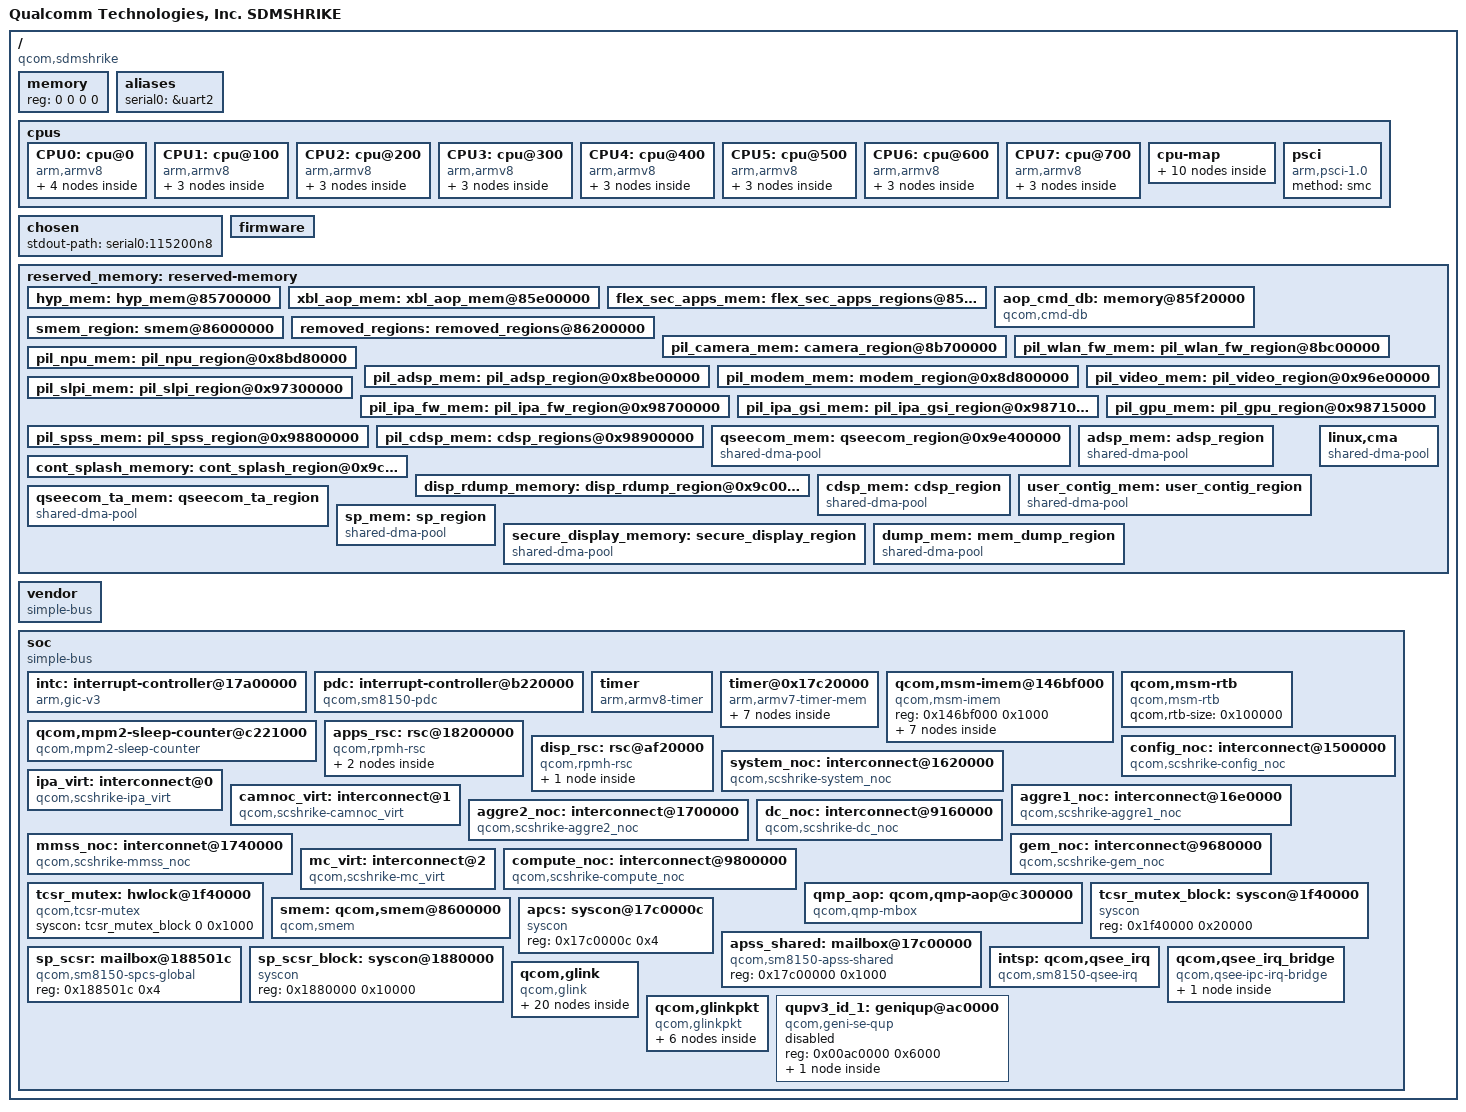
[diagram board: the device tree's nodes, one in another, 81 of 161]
#include <dt-bindings/clock/qcom,rpmh.h>
#include <dt-bindings/interconnect/qcom,icc.h>
#include <dt-bindings/interconnect/qcom,scshrike.h>
#include <dt-bindings/interrupt-controller/arm-gic.h>
#include <dt-bindings/soc/qcom,rpmh-rsc.h>

/ {
	model = "Qualcomm Technologies, Inc. SDMSHRIKE";
	compatible = "qcom,sdmshrike";
	qcom,msm-name = "SDMSHRIKE";
	qcom,msm-id = <340 0x10000>;
	interrupt-parent = <&intc>;

	#address-cells = <2>;
	#size-cells = <2>;
	memory { device_type = "memory"; reg = <0 0 0 0>; };

	aliases {
		serial0 = &uart2;
	};

	cpus {
		#address-cells = <2>;
		#size-cells = <0>;

		CPU0: cpu@0 {
			device_type = "cpu";
			compatible = "arm,armv8";
			reg = <0x0 0x0>;
			enable-method = "psci";
			capacity-dmips-mhz = <1024>;
			cache-size = <0x8000>;
			next-level-cache = <&L2_0>;
			#cooling-cells = <2>;
			L2_0: l2-cache {
			      compatible = "arm,arch-cache";
			      cache-size = <0x20000>;
			      cache-level = <2>;
			      next-level-cache = <&L3_0>;

				L3_0: l3-cache {
				      compatible = "arm,arch-cache";
				      cache-size = <0x400000>;
				      cache-level = <3>;
				};
			};

			L1_I_0: l1-icache {
				compatible = "arm,arch-cache";
				qcom,dump-size = <0xa000>;
			};

			L1_D_0: l1-dcache {
				compatible = "arm,arch-cache";
				qcom,dump-size = <0xa000>;
			};
		};

		CPU1: cpu@100 {
			device_type = "cpu";
			compatible = "arm,armv8";
			reg = <0x0 0x100>;
			enable-method = "psci";
			capacity-dmips-mhz = <1024>;
			cache-size = <0x8000>;
			next-level-cache = <&L2_1>;
			#cooling-cells = <2>;
			L2_1: l2-cache {
			      compatible = "arm,arch-cache";
			      cache-size = <0x20000>;
			      cache-level = <2>;
			      next-level-cache = <&L3_0>;
			};

			L1_I_100: l1-icache {
				compatible = "arm,arch-cache";
				qcom,dump-size = <0xa000>;
			};

			L1_D_100: l1-dcache {
				compatible = "arm,arch-cache";
				qcom,dump-size = <0xa000>;
			};
		};

		CPU2: cpu@200 {
			device_type = "cpu";
			compatible = "arm,armv8";
			reg = <0x0 0x200>;
			enable-method = "psci";
			capacity-dmips-mhz = <1024>;
			cache-size = <0x8000>;
			next-level-cache = <&L2_2>;
			#cooling-cells = <2>;
			L2_2: l2-cache {
			      compatible = "arm,arch-cache";
			      cache-size = <0x20000>;
			      cache-level = <2>;
			      next-level-cache = <&L3_0>;
			};

			L1_I_200: l1-icache {
				compatible = "arm,arch-cache";
				qcom,dump-size = <0xa000>;
			};

			L1_D_200: l1-dcache {
				compatible = "arm,arch-cache";
				qcom,dump-size = <0xa000>;
			};
		};

		CPU3: cpu@300 {
			device_type = "cpu";
			compatible = "arm,armv8";
			reg = <0x0 0x300>;
			enable-method = "psci";
			capacity-dmips-mhz = <1024>;
			cache-size = <0x8000>;
			next-level-cache = <&L2_3>;
			#cooling-cells = <2>;
			L2_3: l2-cache {
			      compatible = "arm,arch-cache";
			      cache-size = <0x20000>;
			      cache-level = <2>;
			      next-level-cache = <&L3_0>;
			};

			L1_I_300: l1-icache {
				compatible = "arm,arch-cache";
				qcom,dump-size = <0xa000>;
			};

			L1_D_300: l1-dcache {
				compatible = "arm,arch-cache";
				qcom,dump-size = <0xa000>;
			};
		};

		CPU4: cpu@400 {
			device_type = "cpu";
			compatible = "arm,armv8";
			reg = <0x0 0x400>;
			enable-method = "psci";
			capacity-dmips-mhz = <1740>;
			cache-size = <0x20000>;
			next-level-cache = <&L2_4>;
			#cooling-cells = <2>;
			L2_4: l2-cache {
			      compatible = "arm,arch-cache";
			      cache-size = <0x80000>;
			      cache-level = <2>;
			      next-level-cache = <&L3_0>;
			};

			L1_I_400: l1-icache {
				compatible = "arm,arch-cache";
				qcom,dump-size = <0x14000>;
			};

			L1_D_400: l1-dcache {
				compatible = "arm,arch-cache";
				qcom,dump-size = <0x14000>;
			};
		};

		CPU5: cpu@500 {
			device_type = "cpu";
			compatible = "arm,armv8";
			reg = <0x0 0x500>;
			enable-method = "psci";
			capacity-dmips-mhz = <1740>;
			cache-size = <0x20000>;
			next-level-cache = <&L2_5>;
			#cooling-cells = <2>;
			L2_5: l2-cache {
			      compatible = "arm,arch-cache";
			      cache-size = <0x80000>;
			      cache-level = <2>;
			      next-level-cache = <&L3_0>;
			};

			L1_I_500: l1-icache {
				compatible = "arm,arch-cache";
				qcom,dump-size = <0x14000>;
			};

			L1_D_500: l1-dcache {
				compatible = "arm,arch-cache";
				qcom,dump-size = <0x14000>;
			};
		};

		CPU6: cpu@600 {
			device_type = "cpu";
			compatible = "arm,armv8";
			reg = <0x0 0x600>;
			enable-method = "psci";
			capacity-dmips-mhz = <1740>;
			cache-size = <0x20000>;
			next-level-cache = <&L2_6>;
			#cooling-cells = <2>;
			L2_6: l2-cache {
			      compatible = "arm,arch-cache";
			      cache-size = <0x80000>;
			      cache-level = <2>;
			      next-level-cache = <&L3_0>;
			};

			L1_I_600: l1-icache {
				compatible = "arm,arch-cache";
				qcom,dump-size = <0x14000>;
			};

			L1_D_600: l1-dcache {
				compatible = "arm,arch-cache";
				qcom,dump-size = <0x14000>;
			};
		};

		CPU7: cpu@700 {
			device_type = "cpu";
			compatible = "arm,armv8";
			reg = <0x0 0x700>;
			enable-method = "psci";
			capacity-dmips-mhz = <1740>;
			cache-size = <0x20000>;
			next-level-cache = <&L2_7>;
			#cooling-cells = <2>;
			L2_7: l2-cache {
			      compatible = "arm,arch-cache";
			      cache-size = <0x80000>;
			      cache-level = <2>;
			      next-level-cache = <&L3_0>;
			};

			L1_I_700: l1-icache {
				compatible = "arm,arch-cache";
				qcom,dump-size = <0x14000>;
			};

			L1_D_700: l1-dcache {
				compatible = "arm,arch-cache";
				qcom,dump-size = <0x14000>;
			};
		};

		cpu-map {
			cluster0 {
				core0 {
					cpu = <&CPU0>;
				};

				core1 {
					cpu = <&CPU1>;
				};

				core2 {
					cpu = <&CPU2>;
				};

				core3 {
					cpu = <&CPU3>;
				};
			};

			cluster1 {
				core0 {
					cpu = <&CPU4>;
				};

				core1 {
					cpu = <&CPU5>;
				};

				core2 {
					cpu = <&CPU6>;
				};

				core3 {
					cpu = <&CPU7>;
				};
			};
		};

		psci {
			compatible = "arm,psci-1.0";
			method = "smc";
		};
	};

	chosen {
		stdout-path = "serial0:115200n8";
	};

	firmware: firmware {
	};

	reserved_memory: reserved-memory {
		#address-cells = <2>;
		#size-cells = <2>;
		ranges;

		hyp_mem: hyp_mem@85700000 {
			no-map;
			reg = <0x0 0x85700000 0x0 0x600000>;
		};

		xbl_aop_mem: xbl_aop_mem@85e00000 {
			no-map;
			reg = <0x0 0x85e00000 0x0 0x140000>;
		};

		flex_sec_apps_mem: flex_sec_apps_regions@85ffd000 {
			no-map;
			reg = <0x0 0x85ffd000 0x0 0x3000>;
		};

		aop_cmd_db: memory@85f20000 {
			compatible = "qcom,cmd-db";
			reg = <0x0 0x85f20000 0x0 0x20000>;
			no-map;
		};

		smem_region: smem@86000000 {
			no-map;
			reg = <0x0 0x86000000 0x0 0x200000>;
		};

		removed_regions: removed_regions@86200000 {
			no-map;
			reg = <0x0 0x86200000 0x0 0x5500000>;
		};

		pil_camera_mem: camera_region@8b700000 {
			no-map;
			reg = <0x0 0x8b700000 0x0 0x500000>;
		};

		pil_wlan_fw_mem: pil_wlan_fw_region@8bc00000 {
			no-map;
			reg = <0x0 0x8bc00000 0x0 0x180000>;
		};

		pil_npu_mem: pil_npu_region@0x8bd80000 {
			no-map;
			reg = <0x0 0x8bd80000 0x0 0x80000>;
		};

		pil_adsp_mem: pil_adsp_region@0x8be00000 {
			no-map;
			reg = <0x0 0x8be00000 0x0 0x1a00000>;
		};

		pil_modem_mem: modem_region@0x8d800000 {
			no-map;
			reg = <0x0 0x8d800000 0x0 0x9600000>;
		};

		pil_video_mem: pil_video_region@0x96e00000 {
			no-map;
			reg = <0x0 0x96e00000 0x0 0x500000>;
		};

		pil_slpi_mem: pil_slpi_region@0x97300000 {
			no-map;
			reg = <0x0 0x97300000 0x0 0x1400000>;
		};

		pil_ipa_fw_mem: pil_ipa_fw_region@0x98700000 {
			no-map;
			reg = <0x0 0x98700000 0x0 0x10000>;
		};

		pil_ipa_gsi_mem: pil_ipa_gsi_region@0x98710000 {
			no-map;
			reg = <0x0 0x98710000 0x0 0x5000>;
		};

		pil_gpu_mem: pil_gpu_region@0x98715000 {
			no-map;
			reg = <0x0 0x98715000 0x0 0x2000>;
		};

		pil_spss_mem: pil_spss_region@0x98800000 {
			no-map;
			reg = <0x0 0x98800000 0x0 0x100000>;
		};

		pil_cdsp_mem: cdsp_regions@0x98900000 {
			no-map;
			reg = <0x0 0x98900000 0x0 0x1400000>;
		};

		qseecom_mem: qseecom_region@0x9e400000 {
			compatible = "shared-dma-pool";
			no-map;
			reg = <0x0 0x9e400000 0x0 0x1400000>;
		};


		cont_splash_memory: cont_splash_region@0x9c000000 {
			reg = <0x0 0x9c000000 0x0 0x02400000>;
			label = "cont_splash_region";
		};

		disp_rdump_memory: disp_rdump_region@0x9c000000 {
			reg = <0x0 0x9c000000 0x0 0x02400000>;
			label = "disp_rdump_region";
		};

		adsp_mem: adsp_region {
			compatible = "shared-dma-pool";
			alloc-ranges = <0x0 0x00000000 0x0 0xffffffff>;
			reusable;
			alignment = <0x0 0x400000>;
			size = <0x0 0x1000000>;
		};

		cdsp_mem: cdsp_region {
			compatible = "shared-dma-pool";
			alloc-ranges = <0x0 0x00000000 0x0 0xffffffff>;
			reusable;
			alignment = <0x0 0x400000>;
			size = <0x0 0x400000>;
		};

		user_contig_mem: user_contig_region {
			compatible = "shared-dma-pool";
			alloc-ranges = <0x0 0x00000000 0x0 0xffffffff>;
			reusable;
			alignment = <0x0 0x400000>;
			size = <0x0 0x1000000>;
		};

		qseecom_ta_mem: qseecom_ta_region {
			compatible = "shared-dma-pool";
			alloc-ranges = <0x0 0x00000000 0x0 0xffffffff>;
			reusable;
			alignment = <0x0 0x400000>;
			size = <0x0 0x1000000>;
		};

		sp_mem: sp_region {  /* SPSS-HLOS ION shared mem */
			compatible = "shared-dma-pool";
			alloc-ranges = <0x0 0x00000000 0x0 0xffffffff>;
			reusable;
			alignment = <0x0 0x400000>;
			size = <0x0 0x800000>;
		};

		secure_display_memory: secure_display_region { /* Secure UI */
			compatible = "shared-dma-pool";
			alloc-ranges = <0x0 0x00000000 0x0 0xffffffff>;
			reusable;
			alignment = <0x0 0x400000>;
			size = <0x0 0xA000000>;
		};

		dump_mem: mem_dump_region {
			compatible = "shared-dma-pool";
			reusable;
			size = <0 0x2400000>;
		};

		/* global autoconfigured region for contiguous allocations */
		linux,cma {
			compatible = "shared-dma-pool";
			alloc-ranges = <0x0 0x00000000 0x0 0xffffffff>;
			reusable;
			alignment = <0x0 0x400000>;
			size = <0x0 0x2800000>;
			linux,cma-default;
		};
	};

	vendor: vendor {
		#address-cells = <1>;
		#size-cells = <1>;
		ranges = <0 0 0 0xffffffff>;
		compatible = "simple-bus";
	};

	soc: soc { };
};

&soc {
	#address-cells = <1>;
	#size-cells = <1>;
	ranges = <0 0 0 0xffffffff>;
	compatible = "simple-bus";

	intc: interrupt-controller@17a00000 {
		compatible = "arm,gic-v3";
		#interrupt-cells = <3>;
		interrupt-controller;
		#redistributor-regions = <1>;
		redistributor-stride = <0x0 0x20000>;
		reg = <0x17a00000 0x10000>,     /* GICD */
		      <0x17a60000 0x100000>;    /* GICR * 8 */
		interrupts = <1 9 4>;
		interrupt-parent = <&intc>;
	};

	pdc: interrupt-controller@b220000 {
		compatible = "qcom,sm8150-pdc";
		reg = <0xb220000 0x30000>, <0x17c000f0 0x64>;
		qcom,pdc-ranges = <0 480 94>, <94 609 31>, <125 63 1>;
		#interrupt-cells = <2>;
		interrupt-parent = <&intc>;
		interrupt-controller;
	};

	timer {
		compatible = "arm,armv8-timer";
		interrupts = <1 1 0xf08>,
			     <1 2 0xf08>,
			     <1 3 0xf08>,
			     <1 0 0xf08>;
		clock-frequency = <19200000>;
	};

	timer@0x17c20000 {
		#address-cells = <1>;
		#size-cells = <1>;
		ranges;
		compatible = "arm,armv7-timer-mem";
		reg = <0x17c20000 0x1000>;
		clock-frequency = <19200000>;

		frame@0x17c21000 {
			frame-number = <0>;
			interrupts = <0 7 0x4>,
				     <0 6 0x4>;
			reg = <0x17c21000 0x1000>,
			      <0x17c22000 0x1000>;
		};

		frame@17c23000 {
			frame-number = <1>;
			interrupts = <0 8 0x4>;
			reg = <0x17c23000 0x1000>;
			status = "disabled";
		};

		frame@17c25000 {
			frame-number = <2>;
			interrupts = <0 9 0x4>;
			reg = <0x17c25000 0x1000>;
			status = "disabled";
		};

		frame@17c27000 {
			frame-number = <3>;
			interrupts = <0 10 0x4>;
			reg = <0x17c26000 0x1000>;
			status = "disabled";
		};

		frame@17c29000 {
			frame-number = <4>;
			interrupts = <0 11 0x4>;
			reg = <0x17c29000 0x1000>;
			status = "disabled";
		};

		frame@17c2b000 {
			frame-number = <5>;
			interrupts = <0 12 0x4>;
			reg = <0x17c2b000 0x1000>;
			status = "disabled";
		};

		frame@17c2d000 {
			frame-number = <6>;
			interrupts = <0 13 0x4>;
			reg = <0x17c2d000 0x1000>;
			status = "disabled";
		};
	};

	qcom,msm-imem@146bf000 {
		compatible = "qcom,msm-imem";
		reg = <0x146bf000 0x1000>;
		ranges = <0x0 0x146bf000 0x1000>;
		#address-cells = <1>;
		#size-cells = <1>;

		mem_dump_table@10 {
			compatible = "qcom,msm-imem-mem_dump_table";
			reg = <0x10 0x8>;
		};

		restart_reason@65c {
			compatible = "qcom,msm-imem-restart_reason";
			reg = <0x65c 0x4>;
		};

		dload_type@1c {
			compatible = "qcom,msm-imem-dload-type";
			reg = <0x1c 0x4>;
		};

		boot_stats@6b0 {
			compatible = "qcom,msm-imem-boot_stats";
			reg = <0x6b0 0x20>;
		};

		kaslr_offset@6d0 {
			compatible = "qcom,msm-imem-kaslr_offset";
			reg = <0x6d0 0xc>;
		};

		pil@94c {
			compatible = "qcom,msm-imem-pil";
			reg = <0x94c 0xc8>;
		};

		diag_dload@c8 {
			compatible = "qcom,msm-imem-diag-dload";
			reg = <0xc8 0xc8>;
		};
	};

	qcom,msm-rtb {
		compatible = "qcom,msm-rtb";
		qcom,rtb-size = <0x100000>;
	};

	qcom,mpm2-sleep-counter@c221000 {
		compatible = "qcom,mpm2-sleep-counter";
		reg = <0xc221000 0x1000>;
		clock-frequency = <32768>;
	};

	apps_rsc: rsc@18200000 {
		label = "apps_rsc";
		compatible = "qcom,rpmh-rsc";
		reg = <0x18200000 0x10000>,
		      <0x18210000 0x10000>,
		      <0x18220000 0x10000>;
		reg-names = "drv-0", "drv-1", "drv-2";
		interrupts = <GIC_SPI 3 IRQ_TYPE_LEVEL_HIGH>,
			     <GIC_SPI 4 IRQ_TYPE_LEVEL_HIGH>,
			     <GIC_SPI 5 IRQ_TYPE_LEVEL_HIGH>;
		qcom,tcs-offset = <0xd00>;
		qcom,drv-id = <2>;
		qcom,tcs-config = <ACTIVE_TCS  2>,
				  <SLEEP_TCS   3>,
				  <WAKE_TCS    3>,
				  <CONTROL_TCS 1>;

		apps_bcm_voter: bcm_voter {
			compatible = "qcom,bcm-voter";
		};

		system_pm {
			compatible = "qcom,system-pm";
		};
	};

	disp_rsc: rsc@af20000 {
		label = "disp_rsc";
		compatible = "qcom,rpmh-rsc";
		reg = <0xaf20000 0x10000>;
		reg-names = "drv-0";
		interrupts = <GIC_SPI 129 IRQ_TYPE_LEVEL_HIGH>;
		qcom,tcs-offset = <0x1c00>;
		qcom,drv-id = <0>;
		qcom,tcs-config = <SLEEP_TCS   1>,
				  <WAKE_TCS    1>,
				  <ACTIVE_TCS  2>,
				  <CONTROL_TCS 0>;

		disp_bcm_voter: bcm_voter {
			compatible = "qcom,bcm-voter";
			qcom,tcs-wait = <QCOM_ICC_TAG_AMC>;
		};
	};

	config_noc: interconnect@1500000 {
		reg = <0x1500000 0x7400>;
		compatible = "qcom,scshrike-config_noc";
		#interconnect-cells = <1>;
		qcom,bcm-voter-names = "hlos";
		qcom,bcm-voters = <&apps_bcm_voter>;
	};

	system_noc: interconnect@1620000 {
		reg = <0x1620000 0x29400>;
		compatible = "qcom,scshrike-system_noc";
		#interconnect-cells = <1>;
		qcom,bcm-voter-names = "hlos";
		qcom,bcm-voters = <&apps_bcm_voter>;
	};

	ipa_virt: interconnect@0 {
		compatible = "qcom,scshrike-ipa_virt";
		#interconnect-cells = <1>;
		qcom,bcm-voter-names = "hlos";
		qcom,bcm-voters = <&apps_bcm_voter>;
	};

	camnoc_virt: interconnect@1 {
		compatible = "qcom,scshrike-camnoc_virt";
		#interconnect-cells = <1>;
		qcom,bcm-voter-names = "hlos";
		qcom,bcm-voters = <&apps_bcm_voter>;
	};

	aggre1_noc: interconnect@16e0000 {
		reg = <0x16E0000 0x1A080>;
		compatible = "qcom,scshrike-aggre1_noc";
		#interconnect-cells = <1>;
		qcom,bcm-voter-names = "hlos";
		qcom,bcm-voters = <&apps_bcm_voter>;
	};

	aggre2_noc: interconnect@1700000 {
		reg = <0x1700000 0x3A080>;
		compatible = "qcom,scshrike-aggre2_noc";
		#interconnect-cells = <1>;
		qcom,bcm-voter-names = "hlos";
		qcom,bcm-voters = <&apps_bcm_voter>;
	};

	mmss_noc: interconnet@1740000 {
		reg = <0x1740000 0x1C100>;
		compatible = "qcom,scshrike-mmss_noc";
		#interconnect-cells = <1>;
		qcom,bcm-voter-names = "hlos", "disp";
		qcom,bcm-voters = <&apps_bcm_voter>, <&disp_bcm_voter>;
	};

	dc_noc: interconnect@9160000 {
		reg = <0x9160000 0x3200>;
		compatible = "qcom,scshrike-dc_noc";
		#interconnect-cells = <1>;
		qcom,bcm-voter-names = "hlos";
		qcom,bcm-voters = <&apps_bcm_voter>;
	};

	gem_noc: interconnect@9680000 {
		reg = <0x9680000 0x3E200>;
		compatible = "qcom,scshrike-gem_noc";
		#interconnect-cells = <1>;
		qcom,bcm-voter-names = "hlos", "disp";
		qcom,bcm-voters = <&apps_bcm_voter>, <&disp_bcm_voter>;
	};

	mc_virt: interconnect@2 {
		compatible = "qcom,scshrike-mc_virt";
		#interconnect-cells = <1>;
		qcom,bcm-voter-names = "hlos", "disp";
		qcom,bcm-voters = <&apps_bcm_voter>, <&disp_bcm_voter>;
	};

	compute_noc: interconnect@9800000 {
		reg = <0x9800000 0x40000>;
		compatible = "qcom,scshrike-compute_noc";
		#interconnect-cells = <1>;
		qcom,bcm-voter-names = "hlos";
		qcom,bcm-voters = <&apps_bcm_voter>;
	};

	qmp_aop: qcom,qmp-aop@c300000 {
		compatible = "qcom,qmp-mbox";
		reg = <0xc300000 0x1000>, <0x17c0000C 0x4>;
		reg-names = "msgram", "irq-reg-base";
		qcom,irq-mask = <0x1>;
		interrupts = <GIC_SPI 389 IRQ_TYPE_EDGE_RISING>;

		label = "aop";
		qcom,early-boot;
		priority = <0>;
		mbox-desc-offset = <0x0>;
		#mbox-cells = <1>;
	};

	tcsr_mutex_block: syscon@1f40000 {
		compatible = "syscon";
		reg = <0x1f40000 0x20000>;
	};

	tcsr_mutex: hwlock@1f40000 {
		compatible = "qcom,tcsr-mutex";
		syscon = <&tcsr_mutex_block 0 0x1000>;
		#hwlock-cells = <1>;
	};

	smem: qcom,smem@8600000 {
		compatible = "qcom,smem";
		memory-region = <&smem_region>;
		hwlocks = <&tcsr_mutex 3>;
	};

	apcs: syscon@17c0000c {
		compatible = "syscon";
		reg = <0x17c0000c 0x4>;
	};

	apss_shared: mailbox@17c00000 {
		compatible = "qcom,sm8150-apss-shared";
		reg = <0x17c00000 0x1000>;

		#mbox-cells = <1>;
	};

	sp_scsr: mailbox@188501c {
		compatible = "qcom,sm8150-spcs-global";
		reg = <0x188501c 0x4>;

		#mbox-cells = <1>;
	};

	sp_scsr_block: syscon@1880000 {
		compatible = "syscon";
		reg = <0x1880000 0x10000>;
	};

	intsp: qcom,qsee_irq {
		compatible = "qcom,sm8150-qsee-irq";

		syscon = <&sp_scsr_block>;
		interrupts = <0 348 IRQ_TYPE_LEVEL_HIGH>,
			     <0 349 IRQ_TYPE_LEVEL_HIGH>;

		interrupt-names = "sp_ipc0",
				  "sp_ipc1";

		interrupt-controller;
		#interrupt-cells = <3>;
	};

	qcom,qsee_irq_bridge {
		compatible = "qcom,qsee-ipc-irq-bridge";

		qcom,qsee-ipc-irq-spss {
			qcom,dev-name = "qsee_ipc_irq_spss";
			label = "spss";
			interrupt-parent = <&intsp>;
			interrupts = <1 0 IRQ_TYPE_LEVEL_HIGH>;
		};
	};

	qcom,glink {
		compatible = "qcom,glink";
		#address-cells = <1>;
		#size-cells = <1>;
		ranges;

		glink_modem: modem {
			qcom,remote-pid = <1>;
			transport = "smem";
			mboxes = <&apss_shared 12>;
			mbox-names = "mpss_smem";
			interrupts = <GIC_SPI 449 IRQ_TYPE_EDGE_RISING>;

			label = "modem";
			qcom,glink-label = "mpss";

			qcom,modem_qrtr {
				qcom,glink-channels = "IPCRTR";
				qcom,low-latency;
				qcom,intents = <0x800  5
						0x2000 3
						0x4400 2>;
			};

			qcom,msm_fastrpc_rpmsg {
				compatible = "qcom,msm-fastrpc-rpmsg";
				qcom,glink-channels = "fastrpcglink-apps-dsp";
				qcom,intents = <0x64 64>;
			};

			qcom,modem_glink_ssr {
				qcom,glink-channels = "glink_ssr";
				qcom,notify-edges = <&glink_adsp>,
						    <&glink_slpi>,
						    <&glink_cdsp>,
						    <&glink_spss>;
			};
		};

		glink_adsp: adsp {
			qcom,remote-pid = <2>;
			transport = "smem";
			mboxes = <&apss_shared 8>;
			mbox-names = "adsp_smem";
			interrupts = <GIC_SPI 156 IRQ_TYPE_EDGE_RISING>;

			label = "adsp";
			qcom,glink-label = "lpass";
			cpu-affinity = <1 2>;

			qcom,adsp_qrtr {
				qcom,glink-channels = "IPCRTR";
				qcom,intents = <0x800  5
						0x2000 3
						0x4400 2>;
			};

			qcom,apr_tal_rpmsg {
				qcom,glink-channels = "apr_audio_svc";
				qcom,intents = <0x200 20>;
			};

			qcom,msm_fastrpc_rpmsg {
				compatible = "qcom,msm-fastrpc-rpmsg";
				qcom,glink-channels = "fastrpcglink-apps-dsp";
				qcom,intents = <0x64 64>;
			};

			qcom,adsp_glink_ssr {
				qcom,glink-channels = "glink_ssr";
				qcom,notify-edges = <&glink_modem>,
						    <&glink_slpi>,
						    <&glink_cdsp>;
			};
		};

		glink_slpi: dsps {
			qcom,remote-pid = <3>;
			transport = "smem";
			mboxes = <&apss_shared 24>;
			mbox-names = "dsps_smem";
			interrupts = <GIC_SPI 170 IRQ_TYPE_EDGE_RISING>;

			label = "slpi";
			qcom,glink-label = "dsps";

			qcom,slpi_qrtr {
				qcom,glink-channels = "IPCRTR";
				qcom,low-latency;
				qcom,intents = <0x800  5
						0x2000 3
						0x4400 2>;
			};

			qcom,msm_fastrpc_rpmsg {
				compatible = "qcom,msm-fastrpc-rpmsg";
				qcom,glink-channels = "fastrpcglink-apps-dsp";
				qcom,intents = <0x64 64>;
			};

			qcom,slpi_glink_ssr {
				qcom,glink-channels = "glink_ssr";
				qcom,notify-edges = <&glink_modem>,
						    <&glink_adsp>,
						    <&glink_cdsp>;
			};
		};

		glink_cdsp: cdsp {
			qcom,remote-pid = <5>;
			transport = "smem";
			mboxes = <&apss_shared 4>;
			mbox-names = "cdsp_smem";
			interrupts = <GIC_SPI 574 IRQ_TYPE_EDGE_RISING>;

			label = "cdsp";
			qcom,glink-label = "cdsp";

			qcom,cdsp_qrtr {
				qcom,glink-channels = "IPCRTR";
				qcom,intents = <0x800  5
						0x2000 3
						0x4400 2>;
			};

			qcom,msm_fastrpc_rpmsg {
				compatible = "qcom,msm-fastrpc-rpmsg";
				qcom,glink-channels = "fastrpcglink-apps-dsp";
				qcom,intents = <0x64 64>;
			};

			qcom,cdsp_glink_ssr {
				qcom,glink-channels = "glink_ssr";
				qcom,notify-edges = <&glink_modem>,
						    <&glink_adsp>,
						    <&glink_slpi>;
			};
		};

		glink_spss: spss {
			qcom,remote-pid = <8>;
			transport = "spss";
			mboxes = <&sp_scsr 0>;
			mbox-names = "spss_spss";
			interrupt-parent = <&intsp>;
			interrupts = <0 0 IRQ_TYPE_LEVEL_HIGH>;

			reg = <0x1885008 0x8>,
			      <0x1885010 0x4>;
			reg-names = "qcom,spss-addr",
				    "qcom,spss-size";

			label = "spss";
			qcom,glink-label = "spss";

			qcom,spss_glink_ssr {
				qcom,glink-channels = "glink_ssr";
				qcom,notify-edges = <&glink_modem>;
			};
		};

		glink_spi_xprt_wdsp: wdsp {
			qcom,remote-pid = <10>;
			transport = "spi";
			tx-descriptors = <0x12000 0x12004>;
			rx-descriptors = <0x1200c 0x12010>;

			label = "wdsp";
			qcom,glink-label = "wdsp";
		};
	};

	qcom,glinkpkt {
		compatible = "qcom,glinkpkt";

		qcom,glinkpkt-at-mdm0 {
			qcom,glinkpkt-edge = "mpss";
			qcom,glinkpkt-ch-name = "DS";
			qcom,glinkpkt-dev-name = "at_mdm0";
		};

		qcom,glinkpkt-apr-apps2 {
			qcom,glinkpkt-edge = "adsp";
			qcom,glinkpkt-ch-name = "apr_apps2";
			qcom,glinkpkt-dev-name = "apr_apps2";
		};

		qcom,glinkpkt-data40-cntl {
			qcom,glinkpkt-edge = "mpss";
			qcom,glinkpkt-ch-name = "DATA40_CNTL";
			qcom,glinkpkt-dev-name = "smdcntl8";
		};

		qcom,glinkpkt-data1 {
			qcom,glinkpkt-edge = "mpss";
			qcom,glinkpkt-ch-name = "DATA1";
			qcom,glinkpkt-dev-name = "smd7";
		};

		qcom,glinkpkt-data4 {
			qcom,glinkpkt-edge = "mpss";
			qcom,glinkpkt-ch-name = "DATA4";
			qcom,glinkpkt-dev-name = "smd8";
		};

		qcom,glinkpkt-data11 {
			qcom,glinkpkt-edge = "mpss";
			qcom,glinkpkt-ch-name = "DATA11";
			qcom,glinkpkt-dev-name = "smd11";
		};
	};

	qupv3_id_1: geniqup@ac0000 {
		compatible = "qcom,geni-se-qup";
		reg = <0x00ac0000 0x6000>;
		ranges;
		#address-cells = <2>;
		#size-cells = <2>;
		status = "disabled";

		uart2: serial@a90000 {
			compatible = "qcom,geni-debug-uart";
			reg = <0x0 0x00a90000 0x0 0x4000>;
			interrupts = <GIC_SPI 357 IRQ_TYPE_LEVEL_HIGH>;
			status = "ok";
		};
	};

};

#include "sdmshrike-pinctrl.dtsi"
#include "sa8195-regulator.dtsi"
#include "sm8150-pm.dtsi"
#include "sa8195-smp2p.dtsi"
